# iospear600 register map
Registers are 32-bit, access not given, no defined reset value unless marked. A register's access mark holds for its fields unless they carry their own. Addresses are absolute; registers are grouped by the start of their names; [hi:lo] are bit positions; {n}, {i} and the like mark numbered series; 'fields as' and 'values as' point back to an identical list.

## PRC1
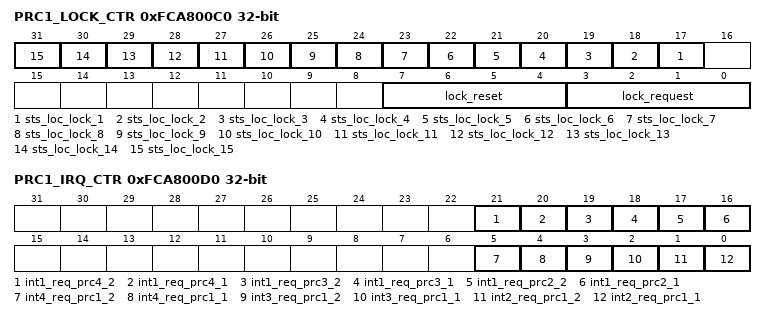
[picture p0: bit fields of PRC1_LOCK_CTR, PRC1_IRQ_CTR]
0xFCA800C0 PRC1_LOCK_CTR
  [n+16] sts_loc_lock_{n} (n=1..15), [7:4] lock_reset, [3:0] lock_request
0xFCA800D0 PRC1_IRQ_CTR
  [21] int1_req_prc4_2, [20] int1_req_prc4_1, [19] int1_req_prc3_2, [18] int1_req_prc3_1, [17] int1_req_prc2_2, [16] int1_req_prc2_1, [5] int4_req_prc1_2, [4] int4_req_prc1_1, [3] int3_req_prc1_2, [2] int3_req_prc1_1, [1] int2_req_prc1_2, [0] int2_req_prc1_1

## PRC2
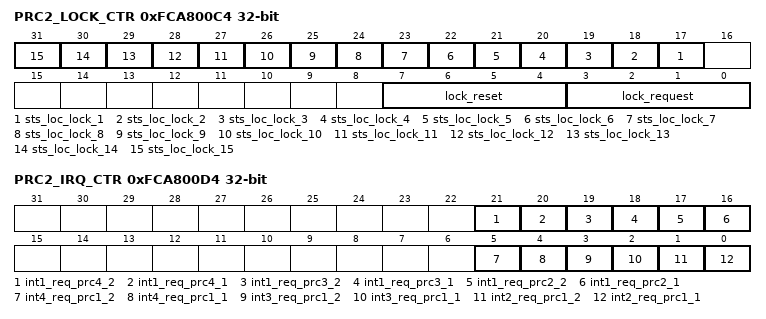
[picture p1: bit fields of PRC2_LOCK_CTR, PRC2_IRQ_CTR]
0xFCA800C4 PRC2_LOCK_CTR
  [n+16] sts_loc_lock_{n} (n=1..15), [7:4] lock_reset, [3:0] lock_request
0xFCA800D4 PRC2_IRQ_CTR
  [21] int1_req_prc4_2, [20] int1_req_prc4_1, [19] int1_req_prc3_2, [18] int1_req_prc3_1, [17] int1_req_prc2_2, [16] int1_req_prc2_1, [5] int4_req_prc1_2, [4] int4_req_prc1_1, [3] int3_req_prc1_2, [2] int3_req_prc1_1, [1] int2_req_prc1_2, [0] int2_req_prc1_1

## PRC3
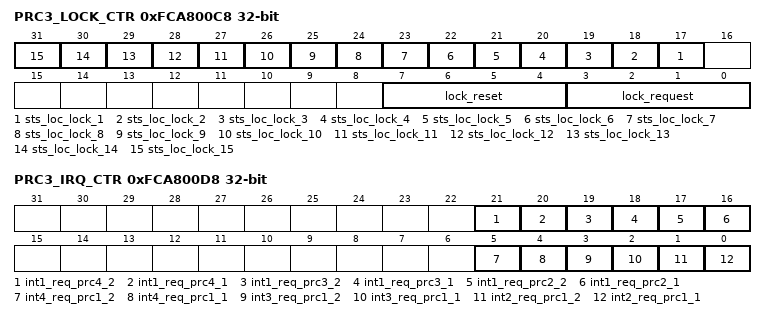
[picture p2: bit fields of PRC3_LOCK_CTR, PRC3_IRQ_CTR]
0xFCA800C8 PRC3_LOCK_CTR
  [n+16] sts_loc_lock_{n} (n=1..15), [7:4] lock_reset, [3:0] lock_request
0xFCA800D8 PRC3_IRQ_CTR
  [21] int1_req_prc4_2, [20] int1_req_prc4_1, [19] int1_req_prc3_2, [18] int1_req_prc3_1, [17] int1_req_prc2_2, [16] int1_req_prc2_1, [5] int4_req_prc1_2, [4] int4_req_prc1_1, [3] int3_req_prc1_2, [2] int3_req_prc1_1, [1] int2_req_prc1_2, [0] int2_req_prc1_1

## PRC4
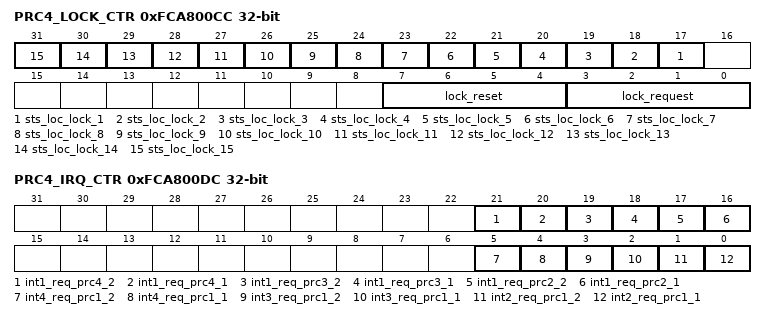
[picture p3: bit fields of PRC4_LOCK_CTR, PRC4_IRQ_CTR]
0xFCA800CC PRC4_LOCK_CTR
  [n+16] sts_loc_lock_{n} (n=1..15), [7:4] lock_reset, [3:0] lock_request
0xFCA800DC PRC4_IRQ_CTR
  [21] int1_req_prc4_2, [20] int1_req_prc4_1, [19] int1_req_prc3_2, [18] int1_req_prc3_1, [17] int1_req_prc2_2, [16] int1_req_prc2_1, [5] int4_req_prc1_2, [4] int4_req_prc1_1, [3] int3_req_prc1_2, [2] int3_req_prc1_1, [1] int2_req_prc1_2, [0] int2_req_prc1_1

## COMPSSTL
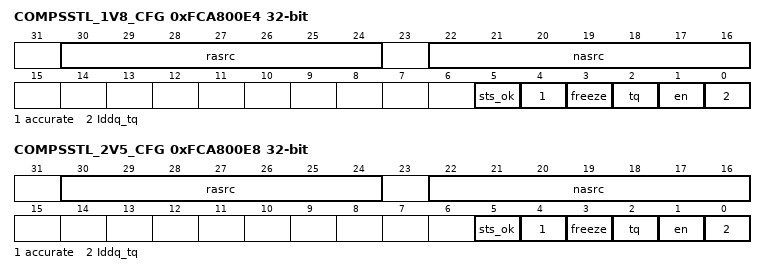
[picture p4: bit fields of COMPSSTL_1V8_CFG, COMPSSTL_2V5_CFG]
0xFCA800E4 COMPSSTL_1V8_CFG
  [30:24] rasrc, [22:16] nasrc, [5] sts_ok, [4] accurate, [3] freeze, [2] tq, [1] en, [0] Iddq_tq
0xFCA800E8 COMPSSTL_2V5_CFG
  fields as COMPSSTL_1V8_CFG

## BIST1
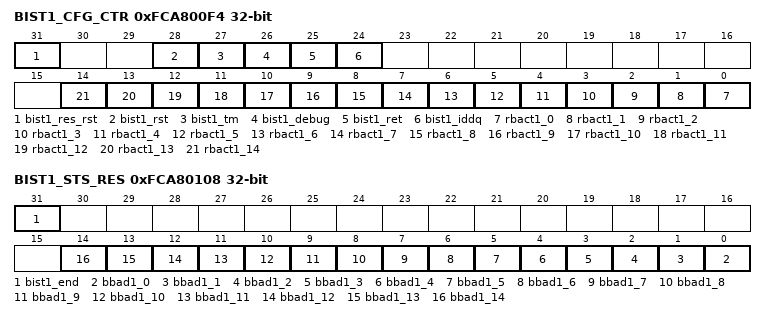
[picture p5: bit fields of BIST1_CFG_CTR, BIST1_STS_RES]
0xFCA800F4 BIST1_CFG_CTR
  [31] bist1_res_rst, [28] bist1_rst, [27] bist1_tm, [26] bist1_debug, [25] bist1_ret, [24] bist1_iddq, [n] rbact1_{n} (n=0..14)
0xFCA80108 BIST1_STS_RES
  [31] bist1_end, [n] bbad1_{n} (n=0..14)

## BIST2
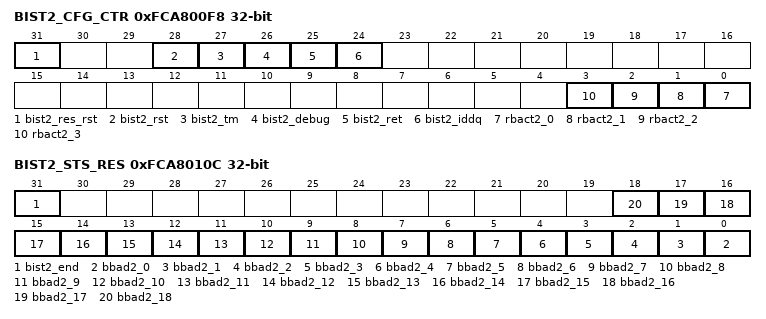
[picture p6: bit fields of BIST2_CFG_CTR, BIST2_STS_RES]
0xFCA800F8 BIST2_CFG_CTR
  [31] bist2_res_rst, [28] bist2_rst, [27] bist2_tm, [26] bist2_debug, [25] bist2_ret, [24] bist2_iddq, [n] rbact2_{n} (n=0..3)
0xFCA8010C BIST2_STS_RES
  [31] bist2_end, [n] bbad2_{n} (n=0..18)

## BIST3
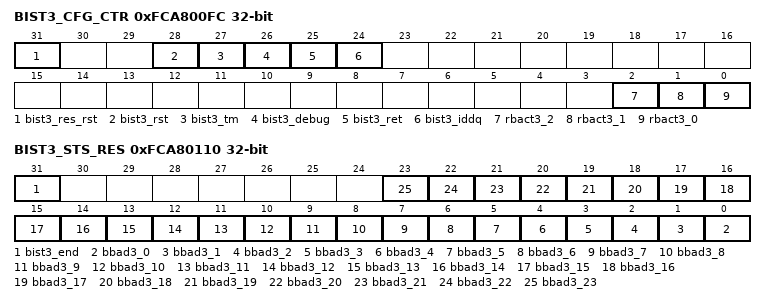
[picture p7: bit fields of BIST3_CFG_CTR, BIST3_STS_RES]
0xFCA800FC BIST3_CFG_CTR
  [31] bist3_res_rst, [28] bist3_rst, [27] bist3_tm, [26] bist3_debug, [25] bist3_ret, [24] bist3_iddq, [2] rbact3_2, [1] rbact3_1, [0] rbact3_0
0xFCA80110 BIST3_STS_RES
  [31] bist3_end, [n] bbad3_{n} (n=0..23)

## BIST4
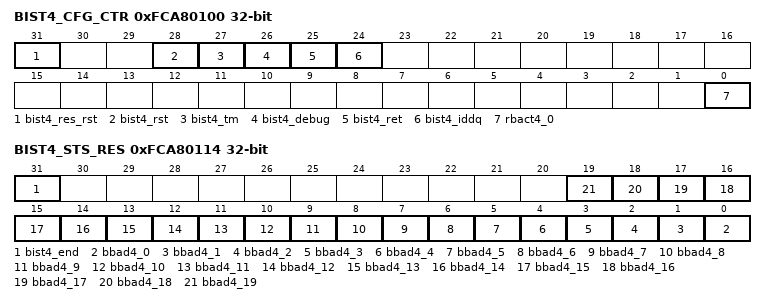
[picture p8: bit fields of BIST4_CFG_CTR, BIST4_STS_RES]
0xFCA80100 BIST4_CFG_CTR
  [31] bist4_res_rst, [28] bist4_rst, [27] bist4_tm, [26] bist4_debug, [25] bist4_ret, [24] bist4_iddq, [0] rbact4_0
0xFCA80114 BIST4_STS_RES
  [31] bist4_end, [n] bbad4_{n} (n=0..19)

## BIST5
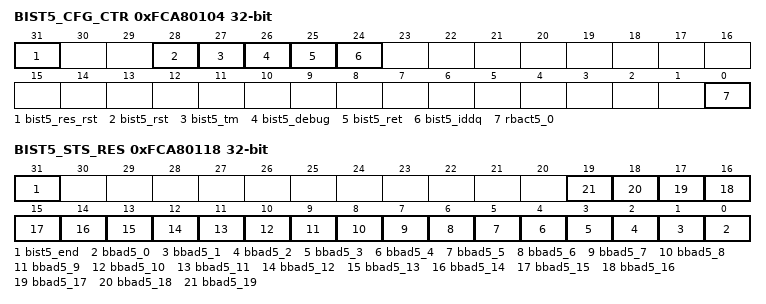
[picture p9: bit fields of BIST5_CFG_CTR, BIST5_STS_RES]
0xFCA80104 BIST5_CFG_CTR
  [31] bist5_res_rst, [28] bist5_rst, [27] bist5_tm, [26] bist5_debug, [25] bist5_ret, [24] bist5_iddq, [0] rbact5_0
0xFCA80118 BIST5_STS_RES
  [31] bist5_end, [n] bbad5_{n} (n=0..19)

## TIMERML
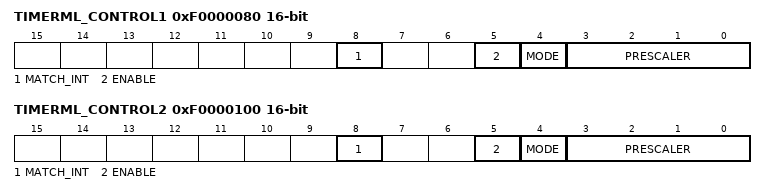
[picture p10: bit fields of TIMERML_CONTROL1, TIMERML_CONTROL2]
0xF0000080 TIMERML_CONTROL1 16-bit
  [8] MATCH_INT, [5] ENABLE, [4] MODE, [3:0] PRESCALER
0xF0000084 TIMERML_STATUS_INT_ACK1 16-bit
  [0] MATCH
0xF0000088 TIMERML_COMPARE1 16-bit
0xF000008C TIMERML_COUNT1 16-bit
0xF0000090 TIMERML_REDG_CAPT1 16-bit
0xF0000094 TIMERML_FEDG_CAPT1 16-bit
0xF0000100 TIMERML_CONTROL2 16-bit
  [8] MATCH_INT, [5] ENABLE, [4] MODE, [3:0] PRESCALER
0xF0000104 TIMERML_STATUS_INT_ACK2 16-bit
  [0] MATCH
0xF0000108 TIMERML_COMPARE2 16-bit
0xF000010C TIMERML_COUNT2 16-bit
0xF0000110 TIMERML_REDG_CAPT2 16-bit
0xF0000114 TIMERML_FEDG_CAPT2 16-bit
